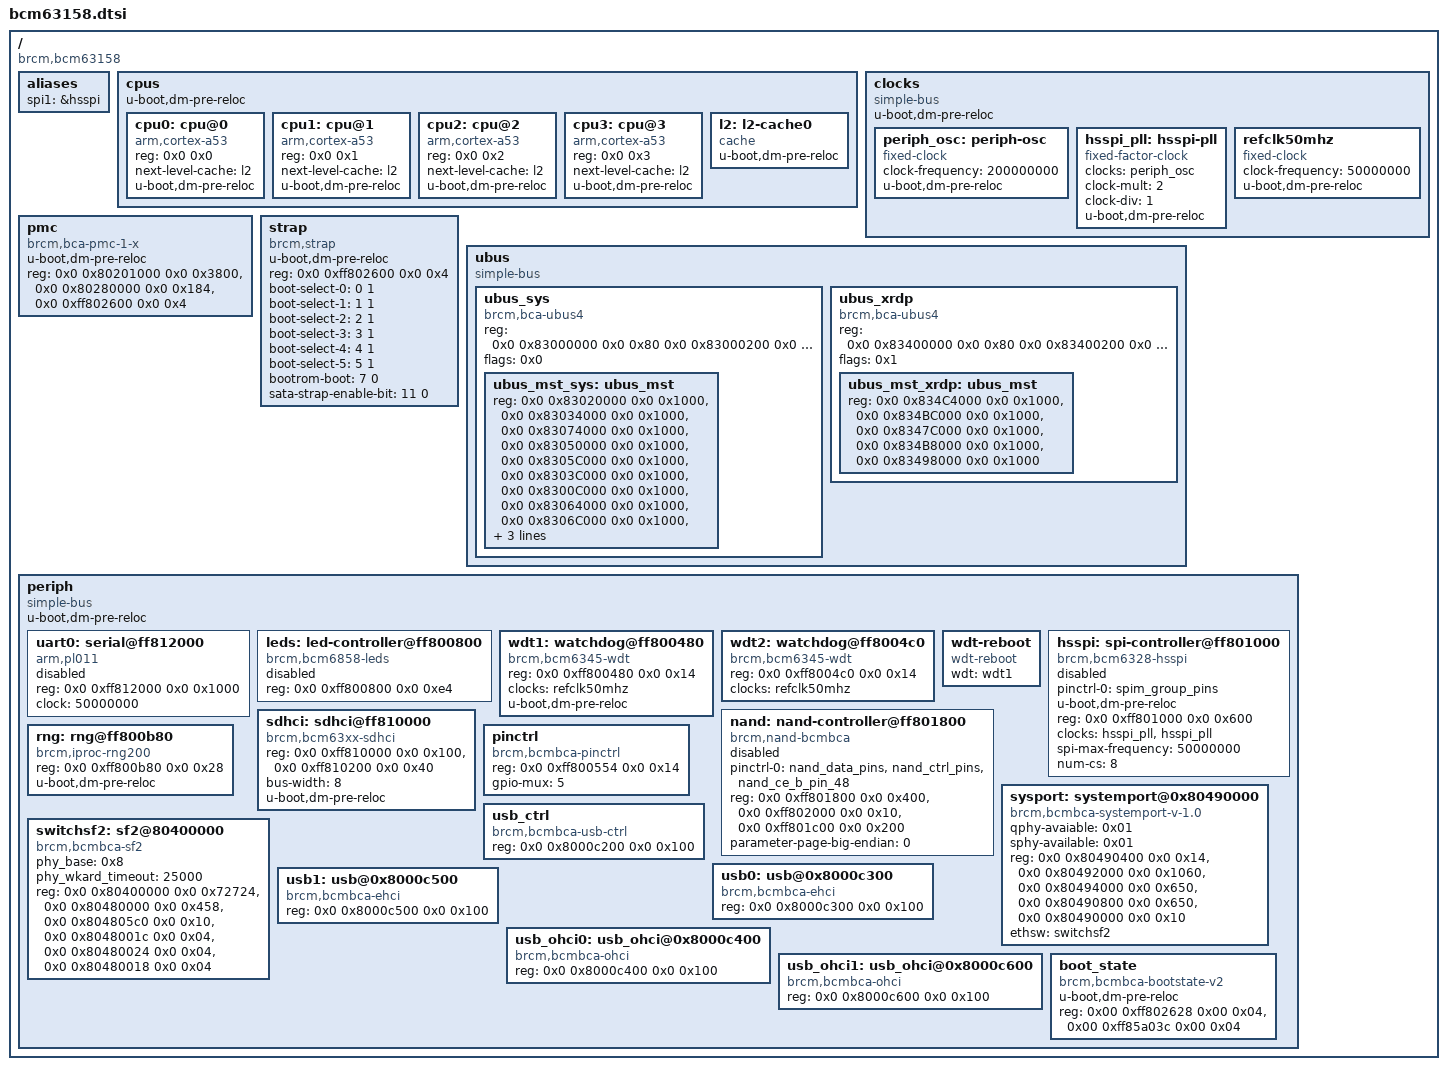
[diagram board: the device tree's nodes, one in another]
// SPDX-License-Identifier: GPL-2.0+
/*
 * Copyright (C) 2019 Philippe Reynes <philippe.reynes@softathome.com>
 */

#include "skeleton64.dtsi"
#include "bcmbca-sf2net.dtsi"

/ {
	compatible = "brcm,bcm63158";
	#address-cells = <2>;
	#size-cells = <2>;

	aliases {
		spi1 = &hsspi;
	};

	cpus {
		#address-cells = <2>;
		#size-cells = <0>;
		u-boot,dm-pre-reloc;

		cpu0: cpu@0 {
			compatible = "arm,cortex-a53", "arm,armv8";
			device_type = "cpu";
			reg = <0x0 0x0>;
			next-level-cache = <&l2>;
			u-boot,dm-pre-reloc;
		};

		cpu1: cpu@1 {
			compatible = "arm,cortex-a53", "arm,armv8";
			device_type = "cpu";
			reg = <0x0 0x1>;
			next-level-cache = <&l2>;
			u-boot,dm-pre-reloc;
		};

		cpu2: cpu@2 {
			compatible = "arm,cortex-a53", "arm,armv8";
			device_type = "cpu";
			reg = <0x0 0x2>;
			next-level-cache = <&l2>;
			u-boot,dm-pre-reloc;
		};

		cpu3: cpu@3 {
			compatible = "arm,cortex-a53", "arm,armv8";
			device_type = "cpu";
			reg = <0x0 0x3>;
			next-level-cache = <&l2>;
			u-boot,dm-pre-reloc;
		};

		l2: l2-cache0 {
			compatible = "cache";
			u-boot,dm-pre-reloc;
		};
	};

	clocks {
		compatible = "simple-bus";
		#address-cells = <2>;
		#size-cells = <2>;
		ranges;
		u-boot,dm-pre-reloc;

		periph_osc: periph-osc {
			compatible = "fixed-clock";
			#clock-cells = <0>;
			clock-frequency = <200000000>;
			u-boot,dm-pre-reloc;
		};

		hsspi_pll: hsspi-pll {
			compatible = "fixed-factor-clock";
			#clock-cells = <0>;
			clocks = <&periph_osc>;
			clock-mult = <2>;
			clock-div = <1>;
			u-boot,dm-pre-reloc;			
		};

		refclk50mhz: refclk50mhz {
			compatible = "fixed-clock";
			#clock-cells = <0>;
			clock-frequency = <50000000>;
			u-boot,dm-pre-reloc;			
		};
	};

	pmc {
		u-boot,dm-pre-reloc;
		compatible = "brcm,bca-pmc-1-x";
		reg = <0x0 0x80201000 0x0 0x3800>,
		    <0x0 0x80280000 0x0 0x184>,
		    <0x0 0xff802600 0x0 0x4>;
		reg-names = "pmc", "procmon", "strap";
    };

	strap: strap {
		u-boot,dm-pre-reloc;	
		compatible = "brcm,strap";
		reg = <0x0 0xff802600 0x0 0x4>;
		boot-select-0=<0 1>;
		boot-select-1=<1 1>;
		boot-select-2=<2 1>;
		boot-select-3=<3 1>;
		boot-select-4=<4 1>;
		boot-select-5=<5 1>;
		bootrom-boot=<7 0>;
		sata-strap-enable-bit=<11 0>;
	};

	/* UBUS */
	ubus: ubus {
		compatible = "simple-bus";
		#address-cells = <2>;
		#size-cells = <2>;
		ranges;

		ubus_sys: ubus_sys {
			#address-cells = <2>;
			#size-cells = <2>;
			compatible = "brcm,bca-ubus4";
			reg = <0x0 0x83000000 0x0 0x80 0x0 0x83000200 0x0 0x80 0x0 0x810a0400 0x0 0x400>;
			reg-names = "ubus_systop", "ubus_registration", "ubus_coherency_port";
			flags = <0x0>;

			ubus_mst_sys: ubus_mst {
				reg-names = "BIU", "PER", "USB", "SPU",
					"DSL", "PERDMA", "PCIE0", "PCIE2",
					"PCIE3", "DSLCPU", "PMC", "SWH";
				reg = <0x0 0x83020000 0x0 0x1000>,
					<0x0 0x83034000 0x0 0x1000>,
					<0x0 0x83074000 0x0 0x1000>,
					<0x0 0x83050000 0x0 0x1000>,
					<0x0 0x8305C000 0x0 0x1000>,
					<0x0 0x8303C000 0x0 0x1000>,
					<0x0 0x8300C000 0x0 0x1000>,
					<0x0 0x83064000 0x0 0x1000>,
					<0x0 0x8306C000 0x0 0x1000>,
					<0x0 0x8301C000 0x0 0x1000>,
					<0x0 0x8302C000 0x0 0x1000>,
					<0x0 0x83048000 0x0 0x1000>;
			};
		};

		ubus_xrdp: ubus_xrdp {
			#address-cells = <2>;
			#size-cells = <2>;
			compatible = "brcm,bca-ubus4";
			reg = <0x0 0x83400000 0x0 0x80 0x0 0x83400200 0x0 0x80>;
			reg-names = "ubus_systop", "ubus_registration";
			flags = <0x1>;

			ubus_mst_xrdp: ubus_mst {
				reg-names = "QM", "DQM", "DMA0", "NATC",
					"RQ0";
				reg = <0x0 0x834C4000 0x0 0x1000>,
					<0x0 0x834BC000 0x0 0x1000>,
					<0x0 0x8347C000 0x0 0x1000>,
					<0x0 0x834B8000 0x0 0x1000>,
					<0x0 0x83498000 0x0 0x1000>;
			};
		};
	};

	periph {
		compatible = "simple-bus";
		#address-cells = <2>;
		#size-cells = <2>;
		u-boot,dm-pre-reloc;

		uart0: serial@ff812000 {
			compatible = "arm,pl011", "arm,primecell";
			reg = <0x0 0xff812000 0x0 0x1000>;
			clock = <50000000>;

			status = "disabled";
		};

		leds: led-controller@ff800800 {
			compatible = "brcm,bcm6858-leds";
			reg = <0x0 0xff800800 0x0 0xe4>;

			status = "disabled";
		};

		wdt1: watchdog@ff800480 {
			compatible = "brcm,bcm6345-wdt";
			reg = <0x0 0xff800480 0x0 0x14>;
			clocks = <&refclk50mhz>;
		        u-boot,dm-pre-reloc;
		};

		wdt2: watchdog@ff8004c0 {
			compatible = "brcm,bcm6345-wdt";
			reg = <0x0 0xff8004c0 0x0 0x14>;
			clocks = <&refclk50mhz>;
		};

		wdt-reboot {
			compatible = "wdt-reboot";
			wdt = <&wdt1>;
		};

		hsspi: spi-controller@ff801000 {
			pinctrl-0 = <&spim_group_pins>;
			pinctrl-names = "default";
			compatible = "brcm,bcm6328-hsspi";
			#address-cells = <1>;
			#size-cells = <0>;
			u-boot,dm-pre-reloc;			
			reg = <0x0 0xff801000 0x0 0x600>;
			clocks = <&hsspi_pll>, <&hsspi_pll>;
			clock-names = "hsspi", "pll";
			spi-max-frequency = <50000000>;
			num-cs = <8>;

			status = "disabled";
		};

		nand: nand-controller@ff801800 {
			pinctrl-0 = <&nand_data_pins &nand_ctrl_pins &nand_ce_b_pin_48>;
			pinctrl-names = "default";
			compatible = "brcm,nand-bcmbca",
				     "brcm,brcmnand-v7.1",
				     "brcm,brcmnand";
			reg-names = "nand", "nand-int-base", "nand-cache";
			reg = <0x0 0xff801800 0x0 0x400>,
			      <0x0 0xff802000 0x0 0x10>,
			      <0x0 0xff801c00 0x0 0x200>;
			parameter-page-big-endian = <0>;

			status = "disabled";
		};

		sdhci: sdhci@ff810000 {
			compatible = "brcm,bcm63xx-sdhci",
			             "brcm,sdhci-brcmbca";
			reg-names = "sdhci-base", "sdhci-boot";
			reg = <0x0 0xff810000 0x0 0x100>,
			      <0x0 0xff810200 0x0 0x40>;	
			bus-width = <8>;
			u-boot,dm-pre-reloc;
		};

		rng: rng@ff800b80 {
			compatible = "brcm,iproc-rng200";
			reg = <0x0 0xff800b80 0x0 0x28>;
			u-boot,dm-pre-reloc;
		};
		sysport: systemport@0x80490000 {
		compatible = "brcm,bcmbca-systemport-v-1.0";
		qphy-avaiable=<0x01>;
		sphy-available=<0x01>;
		reg-names = "systemport-rbuf-base", "systemport-rdma-base",
				"systemport-tdma-base",
				"systemport-umac-base",
				"systemport-topctrl-base";
		reg =	<0x0 0x80490400 0x0 0x14>,
			<0x0 0x80492000 0x0 0x1060>,
			<0x0 0x80494000 0x0 0x650>,
			<0x0 0x80490800 0x0 0x650>,
			<0x0 0x80490000 0x0 0x10>;
		ethsw = <&switchsf2>;
		};

		switchsf2: sf2@80400000 {
		compatible = "brcm,bcmbca-sf2";
		phy_base = <0x8>;
		phy_wkard_timeout = <25000>;
		reg-names = "switchcore-base",
					"switchreg-base",
					"switchmdio-base",
					"qphy-ctrl",
					"sphy-ctrl",
					"phy-test-ctrl";

		reg = <0x0 0x80400000 0x0 0x72724>,
			<0x0 0x80480000 0x0 0x458>,
			<0x0 0x804805c0 0x0 0x10>,
			<0x0 0x8048001c 0x0 0x04>,
			<0x0 0x80480024 0x0 0x04>,
			<0x0 0x80480018 0x0 0x04>;
		};

		pinctrl: pinctrl {
			compatible = "brcm,bcmbca-pinctrl";
			reg = <0x0 0xff800554 0x0 0x14>;
			gpio-mux = <5>;
		};

		usb_ctrl:usb_ctrl {
		compatible = "brcm,bcmbca-usb-ctrl";
		reg-names = "usb-ctrl";
		reg = <0x0 0x8000c200 0x0 0x100>;
		status = "okay";
		};

		usb0: usb@0x8000c300 {
		compatible = "brcm,bcmbca-ehci";
		reg-names = "usb-ehci";
		reg = <0x0 0x8000c300 0x0 0x100>;
		};

		usb1: usb@0x8000c500 {
		compatible = "brcm,bcmbca-ehci";
		reg-names = "usb-ehci";
		reg = <0x0 0x8000c500 0x0 0x100>;
		};

		usb_ohci0: usb_ohci@0x8000c400 {
		compatible = "brcm,bcmbca-ohci";
		reg-names = "usb-ohci";
		reg = <0x0 0x8000c400 0x0 0x100>;
		};

		usb_ohci1: usb_ohci@0x8000c600 {
		compatible = "brcm,bcmbca-ohci";
		reg-names = "usb-ohci";
		reg = <0x0 0x8000c600 0x0 0x100>;
		};

		boot_state {
		u-boot,dm-pre-reloc;
		compatible = "brcm,bcmbca-bootstate-v2";
		reg-names = "reset_reason", "reset_status";
		reg =   <0x00 0xff802628 0x00 0x04>,
			<0x00 0xff85a03c 0x00 0x04>;
		};		
	};
};

#include "bcm63158-pinctrl.dtsi"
